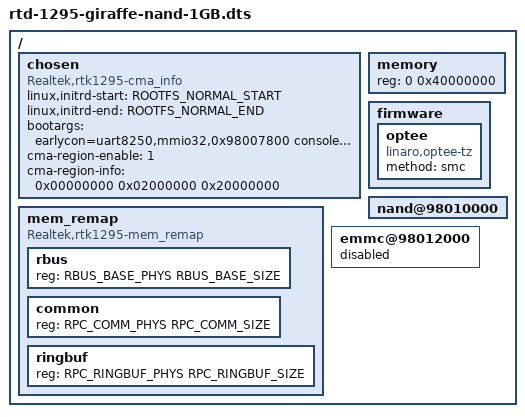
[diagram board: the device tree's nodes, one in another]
/dts-v1/;
#include <dt-bindings/soc/rtk,memory.h>

/memreserve/ SYS_BOOTCODE_MEMBASE       SYS_BOOTCODE_MEMSIZE        ; /* 0x00000000 ~ 0x0002ffff */
/memreserve/ RPC_COMM_PHYS              RPC_COMM_SIZE               ; /* 0x0001f000 ~ 0x0001ffff */
/memreserve/ RPC_RINGBUF_PHYS           RPC_RINGBUF_SIZE            ; /* 0x01ffe000 ~ 0x02001fff */
/memreserve/ ROOTFS_NORMAL_START        ROOTFS_NORMAL_SIZE          ; /* 0x02200000 ~ 0x025fffff */
/memreserve/ ACPU_IDMEM_PHYS            ACPU_IDMEM_SIZE             ; /* 0x10000000 ~ 0x10013fff */

#include "rtd-129x-ion-1GB.dtsi"
#include "rtd-1295.dtsi"
#include "rtd-129x-dvfs.dtsi"
#include "rtd-1295-giraffe-common.dtsi"

/ {
	chosen {
        linux,initrd-start = <ROOTFS_NORMAL_START>;
        linux,initrd-end = <ROOTFS_NORMAL_END>;
        bootargs = "earlycon=uart8250,mmio32,0x98007800 console=ttyS0,115200 init=/init androidboot.hardware=kylin androidboot.heapgrowthlimit=128m androidboot.heapsize=192m androidboot.storage=nand loglevel=4 ubi.mtd=1 rootfstype=ubifs rw root=ubi0_0";
	};

	chosen {
        compatible = "Realtek,rtk1295-cma_info";
        /* NOTE ---------------------------------------------------------------------------------------------*/
        /* <flag size base>                                                                                  */
        /* flag: reserved                                                                                    */
        /* size: unit is byte                                                                                */
        /* base: unit is byte                                                                                */
        /* --------------------------------------------------------------------------------------------------*/
        /* Array size not over 8;                                                                            */
        /* You may change the max array size in KConfig, max CMA array size is CONFIG_CMA_AREAS+1            */
        /* If cma-region-enable is enabled<1>, kernel driver will use cma-region-info to initial CMA memory. */
        /* If cma-region-enable is disabled<0>, kernel driver will use cma= to initial CMA memory.           */
        /* if both setting is loaded, cma-region-info had higher priority.                                   */
        /* --------------------------------------------------------------------------------------------------*/
        cma-region-enable = <1>;
        cma-region-info = <0x00000000 0x02000000 0x20000000>;
        /*cma-region-info = <0x00000000 0x01000000 0x12c00000>, <0x00000000 0x12c00000 0x20000000>;*/
	};

    memory {
        device_type = "memory";
        reg = <0 0x40000000>;   /* 1024 MB */
    };
    firmware {
      optee {
        compatible = "linaro,optee-tz";
        method = "smc";
      };
    };

    mem_remap {
        compatible = "Realtek,rtk1295-mem_remap";
        #address-cells = <1>;
        #size-cells = <1>;
        ranges;
        rbus {
            reg = <RBUS_BASE_PHYS RBUS_BASE_SIZE>;
        };
        common {
            reg = <RPC_COMM_PHYS RPC_COMM_SIZE>;
        };
        ringbuf {
            reg = <RPC_RINGBUF_PHYS RPC_RINGBUF_SIZE>;
        };
    };

    nand@98010000 { status = "okay"; };
    emmc@98012000 { status = "disabled"; }; 

    /*reserved-memory {                                   */
    /*   #address-cells = <1>;                            */
    /*   #size-cells = <1>;                               */
    /*   ranges;                                          */
    /*                                                    */
    /*   tee_reserved: tee {                              */
    /*           no-map;                                  */
    /*           size = <0x00F00000>;                     */
    /*           alloc-ranges = <0x10100000 0x00F00000>;  */
    /*    };                                              */
    /*};	                                              */
};
